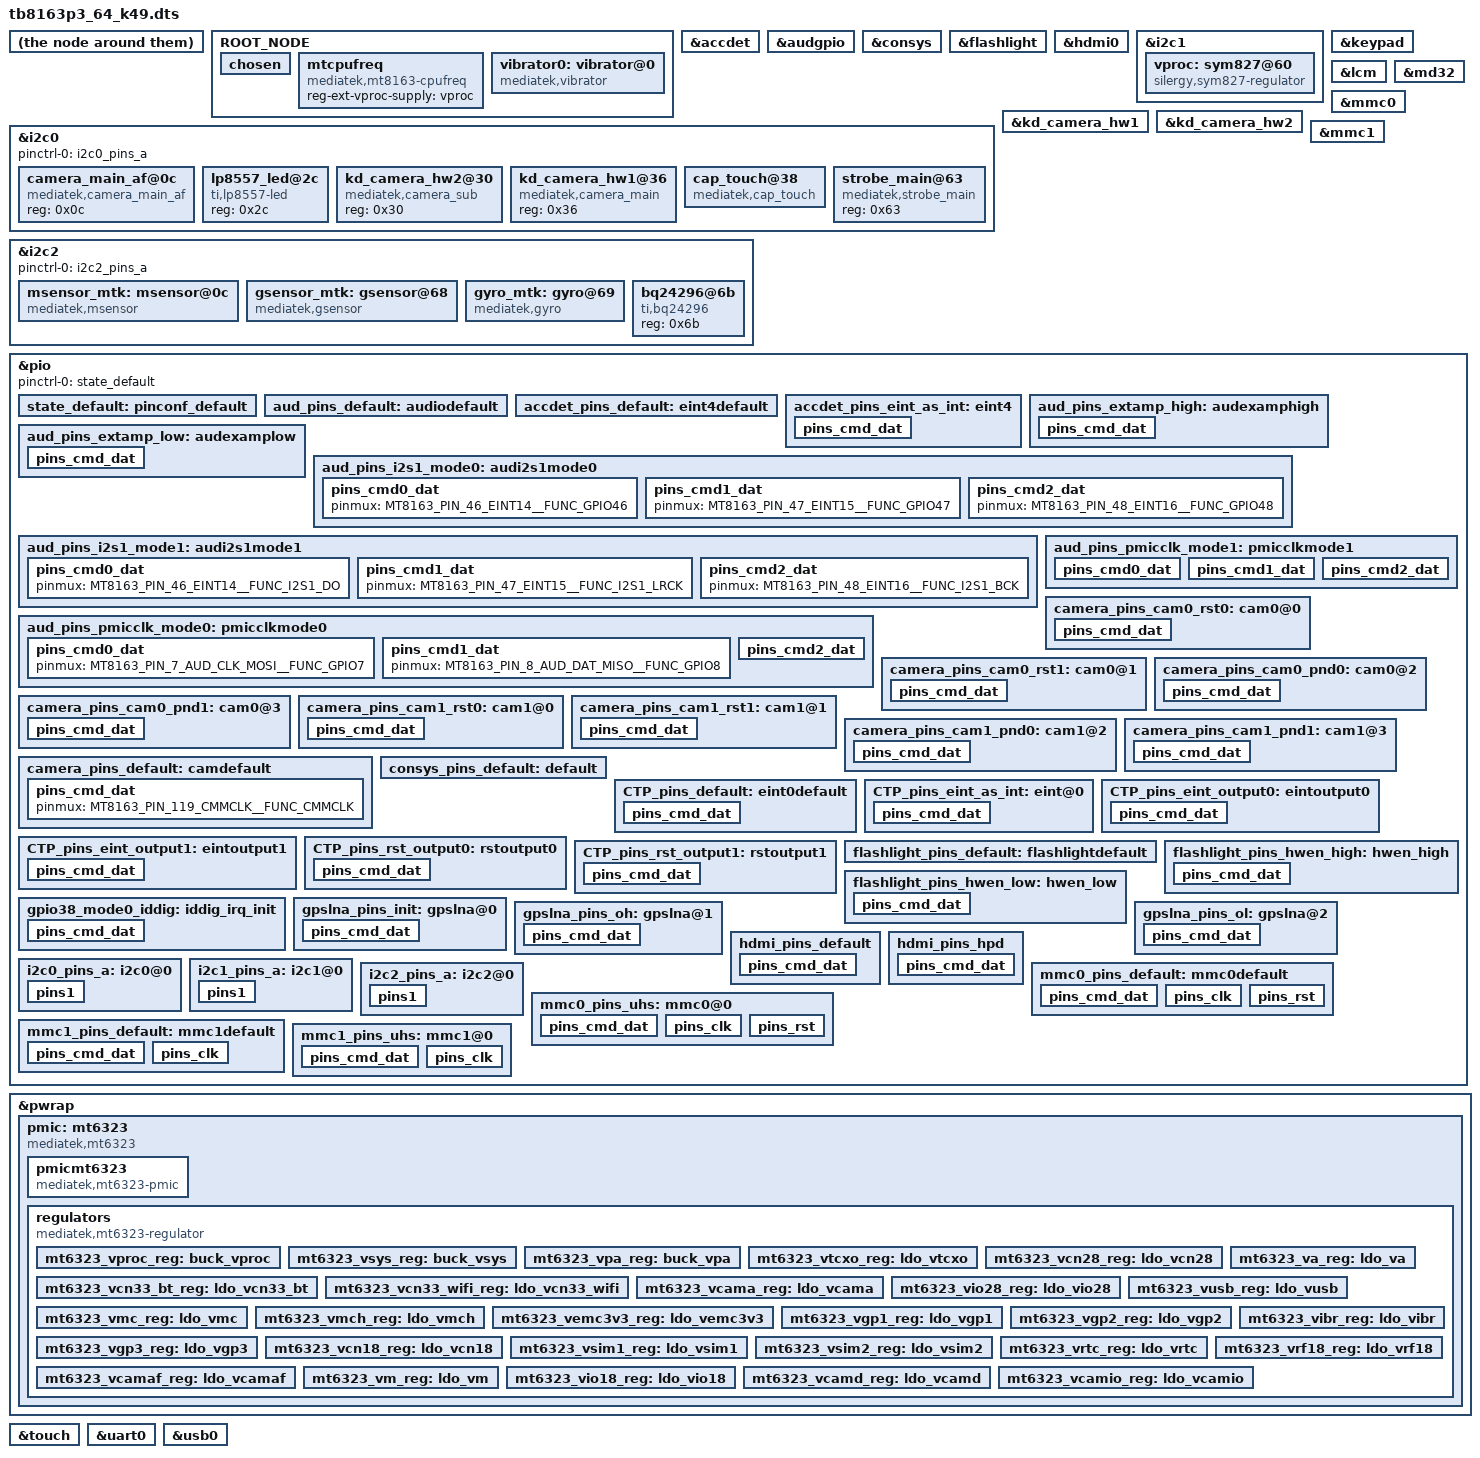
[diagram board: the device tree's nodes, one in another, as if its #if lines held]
/*
 * Copyright (c) 2014-2015 MediaTek Inc.
 *
 * This program is free software; you can redistribute it and/or modify
 * it under the terms of the GNU General Public License version 2 as
 * published by the Free Software Foundation.
 *
 * This program is distributed in the hope that it will be useful,
 * MERCHANTABILITY or FITNESS FOR A PARTICULAR PURPOSE.  See the
 * GNU General Public License for more details.
 */

#include <generated/autoconf.h>
/dts-v1/;

#ifdef CONFIG_MTK_DTBO_FEATURE
/plugin/;
#include <dt-bindings/clock/mt8163-clk.h>
#include <dt-bindings/interrupt-controller/irq.h>
#include <dt-bindings/interrupt-controller/arm-gic.h>
#include "mt8163-pinfunc.h"
#define ROOT_NODE &odm
#else
#include "mt8163.dtsi"
#define ROOT_NODE /
#endif
#include "bat_setting/tb8163p3_64_k49_bat_setting.dtsi"

ROOT_NODE {
	chosen {};

	mtcpufreq {
		compatible = "mediatek,mt8163-cpufreq";
		reg-ext-vproc-supply = <&vproc>;
	};

	vibrator0:vibrator@0 {
		compatible = "mediatek,vibrator";
		vib_timer = <25>;
		vib_limit = <9>;
		vib_vol= <5>;
	};
};

&accdet {
	interrupt-parent = <&pio>;
	interrupts = <4 IRQ_TYPE_LEVEL_LOW>;
	eint-debounce = <256>;
	accdet-gpio = <&pio 26 0>;
	accdet-mic-vol = <7>;
	headset-mode-setting = <0x900 0x400 1 0x3f0 0x800 0x800 0x20>;
	accdet-plugout-debounce = <20>;
	/*1:ACC mode, 2:low cost without in bias, 6:low cost with in bias*/
	accdet-mic-mode = <1>;
	/*0--MD_MAX--UP_MAX--DW_MAX*/
	headset-three-key-threshold = <0 80 220 500>;
	/*0--MD_MAX--VOICE_MAX--UP_MAX--DW_MAX*/
	headset-four-key-threshold = <0 58 121 192 450>;
	pinctrl-names = "default", "state_eint_as_int";
	pinctrl-0 = <&accdet_pins_default>;
	pinctrl-1 = <&accdet_pins_eint_as_int>;
	status = "okay";
};

&audgpio {
	pinctrl-names = "default",
			"audpmicclk-mode0",
			"audpmicclk-mode1",
			"audi2s1-mode0",
			"audi2s1-mode1",
			"extamp-pullhigh",
			"extamp-pulllow";
	pinctrl-0 = <&aud_pins_default>;
	pinctrl-1 = <&aud_pins_pmicclk_mode0>;
	pinctrl-2 = <&aud_pins_pmicclk_mode1>;
	pinctrl-3 = <&aud_pins_i2s1_mode0>;
	pinctrl-4 = <&aud_pins_i2s1_mode1>;
	pinctrl-5 = <&aud_pins_extamp_high>;
	pinctrl-6 = <&aud_pins_extamp_low>;
	status = "okay";
};

&consys {
	pinctrl-names = "default", "gps_lna_state_init", "gps_lna_state_oh", "gps_lna_state_ol";
	pinctrl-0 = <&consys_pins_default>;
	pinctrl-1 = <&gpslna_pins_init>;
	pinctrl-2 = <&gpslna_pins_oh>;
	pinctrl-3 = <&gpslna_pins_ol>;
	vcn18-supply = <&mt6323_vcn18_reg>;
	vcn28-supply = <&mt6323_vcn28_reg>;
	vcn33_bt-supply = <&mt6323_vcn33_bt_reg>;
	vcn33_wifi-supply = <&mt6323_vcn33_wifi_reg>;
	status = "okay";
};

&flashlight {
	pinctrl-names = "default", "hwen_high", "hwen_low";
	pinctrl-0 = <&flashlight_pins_default>;
	pinctrl-1 = <&flashlight_pins_hwen_high>;
	pinctrl-2 = <&flashlight_pins_hwen_low>;
	status = "okay";
};

&hdmi0 {
	pinctrl-names = "default", "hdmi_hpd";
	pinctrl-0 = <&hdmi_pins_default>;
	pinctrl-1 = <&hdmi_pins_hpd>;
	hdmi_power_control = <&pio 27 0>;
};

&i2c0 {
	pinctrl-names = "default";
	pinctrl-0 = <&i2c0_pins_a>;
	status = "okay";

	camera_main_af@0c {
		compatible = "mediatek,camera_main_af";
		reg = <0x0c>;
	};

	lp8557_led@2c {
		compatible = "ti,lp8557-led";
		reg = <0x2c>;
	};

	kd_camera_hw2@30 { /* Fix me to right reg val */
		compatible = "mediatek,camera_sub";
		reg = <0x30>;
	};

	kd_camera_hw1@36 { /* Fix me to right reg val */
		compatible = "mediatek,camera_main";
		reg = <0x36>;
	};

	cap_touch@38 {
		compatible = "mediatek,cap_touch";
		reg = <0x38>;
		interrupt-parent = <&pio>;
		interrupts = <46 IRQ_TYPE_EDGE_FALLING>;
		int-gpio = <&pio 35 0>;
		rst-gpio = <&pio 45 0>;
	};

	strobe_main@63 {
		compatible = "mediatek,strobe_main";
		reg = <0x63>;
	};
};

&i2c1 {
	clock-frequency = <1500000>;
	pinctrl-names = "default";
	pinctrl-0 = <&i2c1_pins_a>;
	status = "okay";

	vproc: sym827@60 {
		compatible = "silergy,sym827-regulator";
		reg = <0x60>;
		regulator-name = "vproc";
		regulator-min-microvolt = <600000>;
		regulator-max-microvolt = <1387500>;
		regulator-enable-ramp-delay = <400>;
		regulator-ramp-delay = <8333>;
		regulator-always-on;
		vsel-gpio = <&pio 34 0>;
	};
};

&i2c2 {
	pinctrl-names = "default";
	pinctrl-0 = <&i2c2_pins_a>;
	status = "okay";

	msensor_mtk: msensor@0c {
		compatible = "mediatek,msensor";
		reg = <0x0c>;
		i2c_num = <2>;
		i2c_addr = <0x0C 0 0 0>;
		direction = <6>;
		power_id = <0xffff>;
		power_vol = <0>;
		is_batch_supported = <0>;
	};

	gsensor_mtk: gsensor@68 {
		compatible = "mediatek,gsensor";
		reg = <0x68>;
		i2c_num	= <2>;
		i2c_addr = <0x68 0 0 0>;
		direction = <7>;
		power_id = <0xffff>;
		power_vol = <0>;
		firlen = <0>;
		is_batch_supported = <0>;
	};

	gyro_mtk: gyro@69 {
		compatible = "mediatek,gyro";
		reg = <0x69>;
		i2c_num = <2>;
		i2c_addr = <0x68 0 0 0>;
		direction = <7>;
		power_id = <0xffff>;
		power_vol = <0>;
		firlen = <0>;
		is_batch_supported = <0>;
	};

	bq24296@6b {
		compatible = "ti,bq24296";
		reg = <0x6b>;
	};
};

/* Main Cam */
&kd_camera_hw1 {
	reg-vcama-supply = <&mt6323_vcama_reg>;		/* AVDD */
	reg-vcamd-supply = <&mt6323_vcamd_reg>;		/* DVDD */
	reg-vcamio-supply = <&mt6323_vcamio_reg>;	/* DOVDD */
	reg-vcamaf-supply = <&mt6323_vcamaf_reg>;	/* AFVDD */

	pinctrl-names = "default", "cam0_rst0", "cam0_rst1", "cam0_pnd0", "cam0_pnd1",
			"cam1_rst0", "cam1_rst1", "cam1_pnd0", "cam1_pnd1","cam_ldo0_0", "cam_ldo0_1";
	pinctrl-0 = <&camera_pins_default>;
	pinctrl-1 = <&camera_pins_cam0_rst0>;
	pinctrl-2 = <&camera_pins_cam0_rst1>;
	pinctrl-3 = <&camera_pins_cam0_pnd0>;
	pinctrl-4 = <&camera_pins_cam0_pnd1>;
	pinctrl-5 = <&camera_pins_cam1_rst0>;
	pinctrl-6 = <&camera_pins_cam1_rst1>;
	pinctrl-7 = <&camera_pins_cam1_pnd0>;
	pinctrl-8 = <&camera_pins_cam1_pnd1>;
/*
	pinctrl-9 = <&camera_pins_cam_ldo0_0>;
	pinctrl-10 = <&camera_pins_cam_ldo0_1>;
*/
	status = "okay";
};

/* Sub Cam */
/* FIX ME: same power pins as Main ? */
&kd_camera_hw2{
	reg-vcama-supply = <&mt6323_vcama_reg>;		/* AVDD */
	reg-vcamd-supply = <&mt6323_vcamd_reg>;		/* DVDD */
	reg-vcamio-supply = <&mt6323_vcamio_reg>;	/* DOVDD */
	reg-vcamaf-supply = <&mt6323_vcamaf_reg>;	/* AFVDD */
};

&keypad {
	mediatek,kpd-key-debounce = <1024>;
	mediatek,kpd-sw-pwrkey = <116>;
	mediatek,kpd-hw-pwrkey = <8>;
	mediatek,kpd-sw-rstkey  = <114>;
	mediatek,kpd-hw-rstkey = <17>;
	mediatek,kpd-use-extend-type = <0>;
	/*HW Keycode [0~71] -> Linux Keycode*/
	mediatek,kpd-hw-map-num = <72>;
	mediatek,kpd-hw-init-map = <115 0 0 0 0 0 0 0 0 0 0 0 0 0 0 0 0 0 0 0 0 0 0 0
			0 0 0 0 0 0 0 0 0 0 0 0 0 0 0 0 0 0 0 0 0 0 0 0
			0 0 0 0 0 0 0 0 0 0 0 0 0 0 0 0 0 0 0 0 0 0 0 0 >;
	mediatek,kpd-pwrkey-eint-gpio = <0>;
	mediatek,kpd-pwkey-gpio-din  = <0>;
	mediatek,kpd-hw-dl-key0 = <0>;
	mediatek,kpd-hw-dl-key1 = <17>;
	mediatek,kpd-hw-dl-key2 = <8>;
	mediatek,kpd-hw-recovery-key = <17>;
	mediatek,kpd-hw-factory-key  = <0>;
};

&lcm {
	lcm_power_gpio = <&pio 84 0>;
	lcm_reset_gpio = <&pio 83 0>;
	reg-lcm-supply = <&mt6323_vgp3_reg>;
};

&md32 {
	status = "okay";
};

&mmc0 {
	pinctrl-names = "default", "state_uhs";
	pinctrl-0 = <&mmc0_pins_default>;
	pinctrl-1 = <&mmc0_pins_uhs>;
	status = "okay";
	bus-width = <8>;
	mediatek,latch-ck = <1>;
	max-frequency = <200000000>;
	cap-mmc-highspeed;
	mmc-hs200-1_8v;
	cap-mmc-hw-reset;
	vmmc-supply = <&mt6323_vemc3v3_reg>;
	vqmmc-supply = <&mt6323_vio18_reg>;
	non-removable;
};

&mmc1 {
	pinctrl-names = "default", "state_uhs";
	pinctrl-0 = <&mmc1_pins_default>;
	pinctrl-1 = <&mmc1_pins_uhs>;
	status = "okay";
	bus-width = <4>;
	mediatek,latch-ck = <1>;
	max-frequency = <200000000>;
	cap-sd-highspeed;
	sd-uhs-sdr50;
	sd-uhs-sdr104;
	broken-cd;
	vmmc-supply = <&mt6323_vmch_reg>;
	vqmmc-supply = <&mt6323_vmc_reg>;
};

&pio {
	pinctrl-names = "default";
	pinctrl-0 = <&state_default>;

	state_default:pinconf_default {
	};

	aud_pins_default: audiodefault {
	};

	accdet_pins_default: eint4default {
	};

	accdet_pins_eint_as_int: eint4 {
		pins_cmd_dat {
			pinmux = <MT8163_PIN_26_EINT4__FUNC_GPIO26>;
			bias-disable;
		};
	};

	aud_pins_extamp_high: audexamphigh {
		pins_cmd_dat {
			pinmux = <MT8163_PIN_24_EINT2__FUNC_GPIO24>;
			slew-rate = <1>;
			output-high;
		};
	};

	aud_pins_extamp_low: audexamplow {
		pins_cmd_dat {
			pinmux = <MT8163_PIN_24_EINT2__FUNC_GPIO24>;
			slew-rate = <1>;
			output-low;
		};
	};

	aud_pins_i2s1_mode0: audi2s1mode0 {
		pins_cmd0_dat {
			pinmux = <MT8163_PIN_46_EINT14__FUNC_GPIO46>;
		};
		pins_cmd1_dat {
			pinmux = <MT8163_PIN_47_EINT15__FUNC_GPIO47>;
		};
		pins_cmd2_dat {
			pinmux = <MT8163_PIN_48_EINT16__FUNC_GPIO48>;
		};
	};

	aud_pins_i2s1_mode1: audi2s1mode1 {
		pins_cmd0_dat {
			pinmux = <MT8163_PIN_46_EINT14__FUNC_I2S1_DO>;
		};
		pins_cmd1_dat {
			pinmux = <MT8163_PIN_47_EINT15__FUNC_I2S1_LRCK>;
		};
		pins_cmd2_dat {
			pinmux = <MT8163_PIN_48_EINT16__FUNC_I2S1_BCK>;
		};
	};

	aud_pins_pmicclk_mode0: pmicclkmode0 {
		pins_cmd0_dat {
			pinmux = <MT8163_PIN_7_AUD_CLK_MOSI__FUNC_GPIO7>;
		};
		pins_cmd1_dat {
			pinmux = <MT8163_PIN_8_AUD_DAT_MISO__FUNC_GPIO8>;
		};
		pins_cmd2_dat {
			pinmux = <MT8163_PIN_9_AUD_DAT_MOSI__FUNC_AUD_DAT_MOSI>;
		};
	};

	aud_pins_pmicclk_mode1: pmicclkmode1 {
		pins_cmd0_dat {
			pinmux = <MT8163_PIN_7_AUD_CLK_MOSI__FUNC_AUD_CLK_MOSI>;
		};
		pins_cmd1_dat {
			pinmux = <MT8163_PIN_8_AUD_DAT_MISO__FUNC_AUD_DAT_MISO>;
		};
		pins_cmd2_dat {
			pinmux = <MT8163_PIN_9_AUD_DAT_MOSI__FUNC_AUD_DAT_MOSI>;
		};
	};

	/* CAMERA GPIO standardization */
	/* Project Dependency : tb8163m1 */
	camera_pins_cam0_rst0: cam0@0 {
		pins_cmd_dat {
			pinmux = <MT8163_PIN_53_SPI_CS__FUNC_GPIO53>;
			/*GPIO_CAMERA_CMRST_PIN*/
			slew-rate = <1>; /*direction 0:in, 1:out*/
			output-low;
			/*direction out used only. output_low or high*/
		};
	};
	camera_pins_cam0_rst1: cam0@1 {
		pins_cmd_dat {
			pinmux = <MT8163_PIN_53_SPI_CS__FUNC_GPIO53>;
			/*GPIO_CAMERA_CMRST_PIN*/
			slew-rate = <1>;
			output-high;
		};
	};
	camera_pins_cam0_pnd0: cam0@2 {
		pins_cmd_dat {
			pinmux = <MT8163_PIN_56_SPI_MO__FUNC_GPIO56>;
			/*GPIO_CAMERA_CMPDN_PIN*/
			slew-rate = <1>;
			output-low;
		};
	};
	camera_pins_cam0_pnd1: cam0@3 {
		pins_cmd_dat {
			pinmux = <MT8163_PIN_56_SPI_MO__FUNC_GPIO56>;
			/*GPIO_CAMERA_CMPDN_PIN*/
			slew-rate = <1>;
			output-high;
		};
	};
	camera_pins_cam1_rst0: cam1@0 {
		pins_cmd_dat {
			pinmux = <MT8163_PIN_55_SPI_MI__FUNC_GPIO55>;
			/*GPIO_CAMERA_CMRST1_PIN*/
			slew-rate = <1>; /*direction 0:in, 1:out*/
			output-low;
			/*direction out used only. output_low or high*/
		};
	};
	camera_pins_cam1_rst1: cam1@1 {
		pins_cmd_dat {
			pinmux = <MT8163_PIN_55_SPI_MI__FUNC_GPIO55>;
			/*GPIO_CAMERA_CMRST1_PIN*/
			slew-rate = <1>;
			output-high;
		};
	};
	camera_pins_cam1_pnd0: cam1@2 {
		pins_cmd_dat {
			pinmux = <MT8163_PIN_54_SPI_CK__FUNC_GPIO54>;
			/*GPIO_CAMERA_CMPDN1_PIN*/
			slew-rate = <1>;
			output-low;
		};
	};
	camera_pins_cam1_pnd1: cam1@3 {
		pins_cmd_dat {
			pinmux = <MT8163_PIN_54_SPI_CK__FUNC_GPIO54>;
			/*GPIO_CAMERA_CMPDN1_PIN*/
			slew-rate = <1>;
			output-high;
		};
	};

/*
	camera_pins_cam_ldo0_0: cam@0 {
		pins_cmd_dat {
			pinmux = <PINMUX_GPIO68__FUNC_GPIO68>;
			slew-rate = <1>;
			output-low;
		};
	};
	camera_pins_cam_ldo0_1: cam@1 {
		pins_cmd_dat {
			pinmux = <PINMUX_GPIO68__FUNC_GPIO68>;
			slew-rate = <1>;
			output-high;
		};
	};
*/

	/* Set MCLK Pin default mode */
	camera_pins_default: camdefault {
		pins_cmd_dat {
			pinmux = <MT8163_PIN_119_CMMCLK__FUNC_CMMCLK>;	/*MCLK*/
		};
	};

	/* CONSYS GPIO Settings - Start */
	consys_pins_default: default {

	};
	/* CONSYS GPIO Settings - End */

	CTP_pins_default: eint0default {
		pins_cmd_dat {
			pinmux = <MT8163_PIN_51_EINT19__FUNC_GPIO51>;
			slew-rate = <0>;
			bias-disable;
		};
	};

	CTP_pins_eint_as_int: eint@0 {
		pins_cmd_dat {
			pinmux = <MT8163_PIN_35_KPROW2__FUNC_GPIO35>;
			slew-rate = <0>;
			bias-disable;
		};
	};

	CTP_pins_eint_output0: eintoutput0 {
		pins_cmd_dat {
			pinmux = <MT8163_PIN_35_KPROW2__FUNC_GPIO35>;
			slew-rate = <1>;
			output-low;
		};
	};

	CTP_pins_eint_output1: eintoutput1 {
		pins_cmd_dat {
			pinmux = <MT8163_PIN_35_KPROW2__FUNC_GPIO35>;
			slew-rate = <1>;
			output-high;
		};
	};

	CTP_pins_rst_output0: rstoutput0 {
		pins_cmd_dat {
			pinmux = <MT8163_PIN_45_EINT13__FUNC_GPIO45>;
			slew-rate = <1>;
			output-low;
		};
	};

	CTP_pins_rst_output1: rstoutput1 {
		pins_cmd_dat {
			pinmux = <MT8163_PIN_45_EINT13__FUNC_GPIO45>;
			slew-rate = <1>;
			output-high;
		};
	};

	flashlight_pins_default: flashlightdefault {
	};

	flashlight_pins_hwen_high: hwen_high {
		pins_cmd_dat {
			pinmux = <MT8163_PIN_117_CMDAT0__FUNC_GPIO117>;
			slew-rate = <1>;
			output-high;
		};
	};

	flashlight_pins_hwen_low: hwen_low {
		pins_cmd_dat {
			pinmux = <MT8163_PIN_117_CMDAT0__FUNC_GPIO117>;
			slew-rate = <1>;
			output-low;
		};
	};

/* USB GPIO start */
	gpio38_mode0_iddig: iddig_irq_init {
		pins_cmd_dat {
			pinmux = <MT8163_PIN_38_KPCOL2__FUNC_GPIO38>;
			slew-rate = <0>;
			bias-pull-up = <00>;
		};
	};
/* USB GPIO end */

	/* CONSYS GPIO Settings - Start */
	gpslna_pins_init: gpslna@0 {
		pins_cmd_dat {
			pinmux = <MT8163_PIN_118_CMDAT1__FUNC_GPIO118>;
			slew-rate = <0>;
			bias-disable;
			output-low;
		};
	};

	gpslna_pins_oh: gpslna@1 {
		pins_cmd_dat {
			pinmux = <MT8163_PIN_118_CMDAT1__FUNC_GPIO118>;
			slew-rate = <1>;
			output-high;
		};
	};

	gpslna_pins_ol: gpslna@2 {
		pins_cmd_dat {
			pinmux = <MT8163_PIN_118_CMDAT1__FUNC_GPIO118>;
			slew-rate = <1>;
			output-low;
		};
	};
	/* CONSYS GPIO Settings - End */

	hdmi_pins_default: hdmi_pins_default {
		pins_cmd_dat {
			pinmux = <MT8163_PIN_27_EINT5__FUNC_GPIO27>;
			slew-rate = <1>;
			bias-pull-up;
			output-high;
		};
	};

	hdmi_pins_hpd: hdmi_pins_hpd {
		pins_cmd_dat {
			pinmux = <MT8163_PIN_139_HTPLG__FUNC_HTPLG>;
			slew-rate = <0>;
			bias-pull-down;
		};
	};

	i2c0_pins_a: i2c0@0 {
		pins1 {
			pinmux = <MT8163_PIN_75_SDA0__FUNC_SDA0_0>,
				 <MT8163_PIN_76_SCL0__FUNC_SCL0_0>;
			bias-disable;
		};
	};

	i2c1_pins_a: i2c1@0 {
		pins1 {
			pinmux = <MT8163_PIN_57_SDA1__FUNC_SDA1_0>,
				 <MT8163_PIN_58_SCL1__FUNC_SCL1_0>;
			bias-disable;
		};
	};

	i2c2_pins_a: i2c2@0 {
		pins1 {
			pinmux = <MT8163_PIN_77_SDA2__FUNC_SDA2_0>,
				 <MT8163_PIN_78_SCL2__FUNC_SCL2_0>;
			bias-disable;
		};
	};

	mmc0_pins_default: mmc0default {
		pins_cmd_dat {
			pinmux = <MT8163_PIN_137_MSDC0_DAT0__FUNC_MSDC0_DAT0>,
				<MT8163_PIN_136_MSDC0_DAT1__FUNC_MSDC0_DAT1>,
				<MT8163_PIN_135_MSDC0_DAT2__FUNC_MSDC0_DAT2>,
				<MT8163_PIN_134_MSDC0_DAT3__FUNC_MSDC0_DAT3>,
				<MT8163_PIN_130_MSDC0_DAT4__FUNC_MSDC0_DAT4>,
				<MT8163_PIN_129_MSDC0_DAT5__FUNC_MSDC0_DAT5>,
				<MT8163_PIN_128_MSDC0_DAT6__FUNC_MSDC0_DAT6>,
				<MT8163_PIN_127_MSDC0_DAT7__FUNC_MSDC0_DAT7>,
				<MT8163_PIN_132_MSDC0_CMD__FUNC_MSDC0_CMD>;
			input-enable;
			bias-pull-up;
		};

		pins_clk {
			pinmux = <MT8163_PIN_133_MSDC0_CLK__FUNC_MSDC0_CLK>;
			bias-pull-down;
		};

		pins_rst {
			pinmux = <MT8163_PIN_131_MSDC0_RSTB__FUNC_MSDC0_RSTB>;
			bias-pull-up;
		};
	};

	mmc0_pins_uhs: mmc0@0{
		pins_cmd_dat {
			pinmux = <MT8163_PIN_137_MSDC0_DAT0__FUNC_MSDC0_DAT0>,
				<MT8163_PIN_136_MSDC0_DAT1__FUNC_MSDC0_DAT1>,
				<MT8163_PIN_135_MSDC0_DAT2__FUNC_MSDC0_DAT2>,
				<MT8163_PIN_134_MSDC0_DAT3__FUNC_MSDC0_DAT3>,
				<MT8163_PIN_130_MSDC0_DAT4__FUNC_MSDC0_DAT4>,
				<MT8163_PIN_129_MSDC0_DAT5__FUNC_MSDC0_DAT5>,
				<MT8163_PIN_128_MSDC0_DAT6__FUNC_MSDC0_DAT6>,
				<MT8163_PIN_127_MSDC0_DAT7__FUNC_MSDC0_DAT7>,
				<MT8163_PIN_132_MSDC0_CMD__FUNC_MSDC0_CMD>;
			input-enable;
			drive-strength = <MTK_DRIVE_6mA>;
			bias-pull-up = <MTK_PUPD_SET_R1R0_01>;
		};

		pins_clk {
			pinmux = <MT8163_PIN_133_MSDC0_CLK__FUNC_MSDC0_CLK>;
			drive-strength = <MTK_DRIVE_6mA>;
			bias-pull-down = <MTK_PUPD_SET_R1R0_01>;
		};

		pins_rst {
			pinmux = <MT8163_PIN_131_MSDC0_RSTB__FUNC_MSDC0_RSTB>;
			bias-pull-up;
		};
	};

	mmc1_pins_default: mmc1default {
		pins_cmd_dat {
			pinmux = <MT8163_PIN_123_MSDC1_DAT0__FUNC_MSDC1_DAT0>,
				<MT8163_PIN_124_MSDC1_DAT1__FUNC_MSDC1_DAT1>,
				<MT8163_PIN_125_MSDC1_DAT2__FUNC_MSDC1_DAT2>,
				<MT8163_PIN_126_MSDC1_DAT3__FUNC_MSDC1_DAT3>,
				<MT8163_PIN_121_MSDC1_CMD__FUNC_MSDC1_CMD>;
			input-enable;
			drive-strength = <MTK_DRIVE_8mA>;
			bias-pull-up = <MTK_PUPD_SET_R1R0_10>;
		};

		pins_clk {
			pinmux = <MT8163_PIN_122_MSDC1_CLK__FUNC_MSDC1_CLK>;
			bias-pull-down;
			drive-strength = <MTK_DRIVE_8mA>;
		};
	};

	mmc1_pins_uhs: mmc1@0 {
		pins_cmd_dat {
			pinmux = <MT8163_PIN_123_MSDC1_DAT0__FUNC_MSDC1_DAT0>,
				<MT8163_PIN_124_MSDC1_DAT1__FUNC_MSDC1_DAT1>,
				<MT8163_PIN_125_MSDC1_DAT2__FUNC_MSDC1_DAT2>,
				<MT8163_PIN_126_MSDC1_DAT3__FUNC_MSDC1_DAT3>,
				<MT8163_PIN_121_MSDC1_CMD__FUNC_MSDC1_CMD>;
			input-enable;
			drive-strength = <MTK_DRIVE_4mA>;
			bias-pull-up = <MTK_PUPD_SET_R1R0_10>;
		};

		pins_clk {
			pinmux = <MT8163_PIN_122_MSDC1_CLK__FUNC_MSDC1_CLK>;
			drive-strength = <MTK_DRIVE_4mA>;
			bias-pull-down = <MTK_PUPD_SET_R1R0_10>;
		};
	};
};

&pwrap {
	pmic: mt6323 {
		compatible = "mediatek,mt6323";

		pmicmt6323: pmicmt6323 {
			compatible = "mediatek,mt6323-pmic";
			interrupt-parent = <&pio>;
			interrupts = <24 IRQ_TYPE_LEVEL_HIGH>;
		};

		regulators {

			compatible = "mediatek,mt6323-regulator";

			mt6323_vproc_reg: buck_vproc {
				regulator-name = "vproc";
				regulator-min-microvolt = < 700000>;
				regulator-max-microvolt = <1350000>;
				regulator-ramp-delay = <12500>;
				regulator-always-on;
				regulator-boot-on;
			};

			mt6323_vsys_reg: buck_vsys {
				regulator-name = "vsys";
				regulator-min-microvolt = <1400000>;
				regulator-max-microvolt = <2987500>;
				regulator-ramp-delay = <25000>;
				regulator-always-on;
				regulator-boot-on;
			};

			mt6323_vpa_reg: buck_vpa {
				regulator-name = "vpa";
				regulator-min-microvolt = < 500000>;
				regulator-max-microvolt = <3650000>;
			};

			mt6323_vtcxo_reg: ldo_vtcxo {
				regulator-name = "vtcxo";
				regulator-min-microvolt = <2800000>;
				regulator-max-microvolt = <2800000>;
				regulator-enable-ramp-delay = <90>;
				regulator-always-on;
				regulator-boot-on;
			};

			mt6323_vcn28_reg: ldo_vcn28 {
				regulator-name = "vcn28";
				regulator-min-microvolt = <2800000>;
				regulator-max-microvolt = <2800000>;
				regulator-enable-ramp-delay = <185>;
			};

			mt6323_vcn33_bt_reg: ldo_vcn33_bt {
				regulator-name = "vcn33_bt";
				regulator-min-microvolt = <3300000>;
				regulator-max-microvolt = <3600000>;
				regulator-enable-ramp-delay = <185>;
			};

			mt6323_vcn33_wifi_reg: ldo_vcn33_wifi {
				regulator-name = "vcn33_wifi";
				regulator-min-microvolt = <3300000>;
				regulator-max-microvolt = <3600000>;
				regulator-enable-ramp-delay = <185>;
			};

			mt6323_va_reg: ldo_va {
				regulator-name = "va";
				regulator-min-microvolt = <2800000>;
				regulator-max-microvolt = <2800000>;
				regulator-enable-ramp-delay = <216>;
				regulator-always-on;
				regulator-boot-on;
			};

			mt6323_vcama_reg: ldo_vcama {
				regulator-name = "vcama";
				regulator-min-microvolt = <1500000>;
				regulator-max-microvolt = <2800000>;
				regulator-enable-ramp-delay = <216>;
			};

			mt6323_vio28_reg: ldo_vio28 {
				regulator-name = "vio28";
				regulator-min-microvolt = <2800000>;
				regulator-max-microvolt = <2800000>;
				regulator-enable-ramp-delay = <216>;
				regulator-always-on;
				regulator-boot-on;
			};

			mt6323_vusb_reg: ldo_vusb {
				regulator-name = "vusb";
				regulator-min-microvolt = <3300000>;
				regulator-max-microvolt = <3300000>;
				regulator-enable-ramp-delay = <216>;
				regulator-boot-on;
			};

			mt6323_vmc_reg: ldo_vmc {
				regulator-name = "vmc";
				regulator-min-microvolt = <1800000>;
				regulator-max-microvolt = <3300000>;
				regulator-enable-ramp-delay = <36>;
				regulator-boot-on;
			};

			mt6323_vmch_reg: ldo_vmch {
				regulator-name = "vmch";
				regulator-min-microvolt = <3000000>;
				regulator-max-microvolt = <3300000>;
				regulator-enable-ramp-delay = <36>;
				regulator-boot-on;
			};

			mt6323_vemc3v3_reg: ldo_vemc3v3 {
				regulator-name = "vemc3v3";
				regulator-min-microvolt = <3000000>;
				regulator-max-microvolt = <3300000>;
				regulator-enable-ramp-delay = <36>;
				regulator-boot-on;
			};

			mt6323_vgp1_reg: ldo_vgp1 {
				regulator-name = "vgp1";
				regulator-min-microvolt = <1200000>;
				regulator-max-microvolt = <3300000>;
				regulator-enable-ramp-delay = <216>;
			};

			mt6323_vgp2_reg: ldo_vgp2 {
				regulator-name = "vgp2";
				regulator-min-microvolt = <1200000>;
				regulator-max-microvolt = <3000000>;
				regulator-enable-ramp-delay = <216>;
			};

			mt6323_vgp3_reg: ldo_vgp3 {
				regulator-name = "vgp3";
				regulator-min-microvolt = <1200000>;
				regulator-max-microvolt = <1800000>;
				regulator-enable-ramp-delay = <216>;
			};

			mt6323_vcn18_reg: ldo_vcn18 {
				regulator-name = "vcn18";
				regulator-min-microvolt = <1800000>;
				regulator-max-microvolt = <1800000>;
				regulator-enable-ramp-delay = <216>;
			};

			mt6323_vsim1_reg: ldo_vsim1 {
				regulator-name = "vsim1";
				regulator-min-microvolt = <1800000>;
				regulator-max-microvolt = <3000000>;
				regulator-enable-ramp-delay = <216>;
			};

			mt6323_vsim2_reg: ldo_vsim2 {
				regulator-name = "vsim2";
				regulator-min-microvolt = <1800000>;
				regulator-max-microvolt = <3000000>;
				regulator-enable-ramp-delay = <216>;
			};

			mt6323_vrtc_reg: ldo_vrtc {
				regulator-name = "vrtc";
				regulator-min-microvolt = <2800000>;
				regulator-max-microvolt = <2800000>;
				regulator-always-on;
				regulator-boot-on;
			};

			mt6323_vcamaf_reg: ldo_vcamaf {
				regulator-name = "vcamaf";
				regulator-min-microvolt = <1200000>;
				regulator-max-microvolt = <3300000>;
				regulator-enable-ramp-delay = <216>;
			};

			mt6323_vibr_reg: ldo_vibr {
				regulator-name = "vibr";
				regulator-min-microvolt = <1200000>;
				regulator-max-microvolt = <3300000>;
				regulator-enable-ramp-delay = <36>;
			};

			mt6323_vrf18_reg: ldo_vrf18 {
				regulator-name = "vrf18";
				regulator-min-microvolt = <1825000>;
				regulator-max-microvolt = <1825000>;
				regulator-enable-ramp-delay = <187>;
			};

			mt6323_vm_reg: ldo_vm {
				regulator-name = "vm";
				regulator-min-microvolt = <1200000>;
				regulator-max-microvolt = <1800000>;
				regulator-enable-ramp-delay = <216>;
				regulator-always-on;
				regulator-boot-on;
			};

			mt6323_vio18_reg: ldo_vio18 {
				regulator-name = "vio18";
				regulator-min-microvolt = <1800000>;
				regulator-max-microvolt = <1800000>;
				regulator-enable-ramp-delay = <216>;
				regulator-always-on;
				regulator-boot-on;
			};

			mt6323_vcamd_reg: ldo_vcamd {
				regulator-name = "vcamd";
				regulator-min-microvolt = <1200000>;
				regulator-max-microvolt = <1800000>;
				regulator-enable-ramp-delay = <216>;
			};

			mt6323_vcamio_reg: ldo_vcamio {
				regulator-name = "vcamio";
				regulator-min-microvolt = <1800000>;
				regulator-max-microvolt = <1800000>;
				regulator-enable-ramp-delay = <216>;
			};
		};
	};
};

&touch {
	vtouch-supply = <&mt6323_vgp2_reg>;
	tpd-resolution = <800 1280>;
	use-tpd-button = <0>;
	tpd-key-num = <4>;
	tpd-key-local= <139 172 158 0>;
	tpd-key-dim-local = <60 850 50 30 180 850 50 30 300 850 50 30 420 850 50 30>;
	tpd-max-touch-num = <5>;
	tpd-filter-enable = <1>;
	tpd-filter-pixel-density = <124>;
	tpd-filter-custom-prameters = <0 0 0 0 0 0 0 0 0 0 0 0>;
	tpd-filter-custom-speed = <0 0 0>;
	pinctrl-names = "default", "state_eint_as_int", "state_eint_output0",
			"state_eint_output1", "state_rst_output0",
			"state_rst_output1";
	pinctrl-0 = <&CTP_pins_default>;
	pinctrl-1 = <&CTP_pins_eint_as_int>;
	pinctrl-2 = <&CTP_pins_eint_output0>;
	pinctrl-3 = <&CTP_pins_eint_output1>;
	pinctrl-4 = <&CTP_pins_rst_output0>;
	pinctrl-5 = <&CTP_pins_rst_output1>;
	status = "okay";
};

&uart0 {
	status="okay";
};

&usb0 {
	vusb-supply = <&mt6323_vusb_reg>;
	pinctrl-names = "iddig_irq_init";
	pinctrl-0 = <&gpio38_mode0_iddig>;
	iddig_gpio = <&pio 38 0>;
	status = "okay";
};
